# apollo4b register map
Vendor: Ambiq Micro; Series: Apollo; File version: 1.0
CPU: CM4 r1p0, little endian, MPU, FPU, I-cache, D-cache, VTOR, ITCM, DTCM, 3 interrupt priority bits, 0 interrupts
Registers are 32-bit, read-write, reset 0x0 unless marked. A register's access mark holds for its fields unless they carry their own. Offsets are from the block's base; [hi:lo] are bit positions; 'fields as' and 'values as' point back to an identical list.

## IOM0 — IO Peripheral Master
Base 0x40050000
Same registers: IOM1 0x40051000, IOM2 0x40052000, IOM3 0x40053000, IOM4 0x40054000, IOM5 0x40055000, IOM6 0x40056000, IOM7 0x40057000
0x00 FIFO — Provides direct random access to both input and output fifos. The state of the FIFO is not distured by reading these locations (ie no POP will be done). FIFO0 is accessible from addresses 0x0 - 0x1C, and is used for data outuput from the IOM to external devices. These FIFO locations can be read and written directly. FIFO locations 0x20 - 0x3C provide read only access to the input fifo. These FIFO locations cannot be directly written by the MCU, and are updated only by the internal hardware. Writes to the FIFO0 will take effect immediately. The currently FIFO pointers in register FIFOLOC indicate the current offset into each FIFO0 for the read and write operations. Access to the FIFOs can only be done in word increments; Byte access and writes are not supported. For push and pop style access to FIFO0 can be done using the FIFOPOP and FIFOPUSH registers below.
  [31:0] FIFO — FIFO direct access. Only locations 0 - 3F will return valid information.
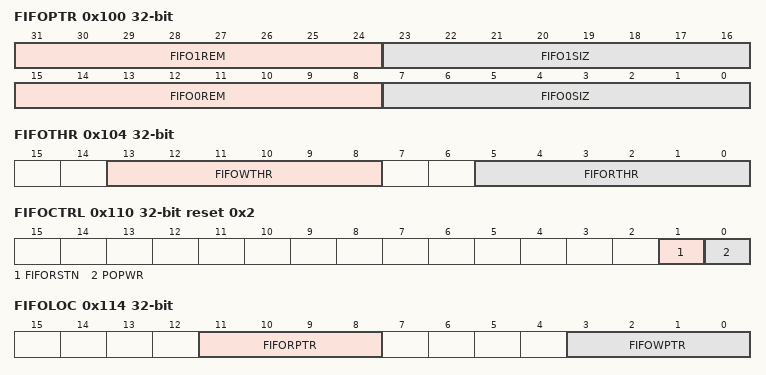
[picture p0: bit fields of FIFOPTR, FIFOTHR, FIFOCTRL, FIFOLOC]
0x100 FIFOPTR — Provides the current valid byte count of data within the FIFO as seen from the internal state machines. FIFO0 is dedicated to outgoing transactions and FIFO1 is dedicated to incoming transactions. All counts are specified in units of bytes.
  [31:24] FIFO1REM — The number of remaining data bytes slots currently in FIFO 1 (written by interface, read by MCU)
  [23:16] FIFO1SIZ — The number of valid data bytes currently in FIFO 1 (written by interface, read by MCU)
  [15:8] FIFO0REM — The number of remaining data bytes slots currently in FIFO 0 (written by MCU, read by interface)
  [7:0] FIFO0SIZ — The number of valid data bytes currently in the FIFO 0 (written by MCU, read by interface)
0x104 FIFOTHR — Sets the threshold values for incoming and outgoing transactions. The threshold values are used to assert the interrupt if enabled, and also used during DMA to set the transfer size as a result of DMATHR trigger. The WTHR is used to indicate when there are more than WTHR bytes of open fifo locations available in the outgoing FIFO (FIFO0). The intended use to invoke an interrupt or DMA transfer that will refill the FIFO with a byte count up to this value. The RTHR is used to indicate when there are more than RTHR bytes in the incoming FIFO (FIFO1) and a data transfer of this size can be supported, either through direct POP of the FIFO, or through DMA. The value of both RTHR and WTHR are also used to set the data transfer size of DMA operations if DMATHR trigger is enabled.
  [13:8] FIFOWTHR — FIFO write threshold in bytes. A value of 0 will disable the write FIFO level from activating the threshold interrupt. If this field is non-zero, it will trigger a threshold interrupt when the write fifo contains FIFOWTHR free bytes, as indicated by the FIFO0REM field. This is intended to signal when a transfer of FIFOWTHR bytes can be done from the host to the IOM write fifo to support large IOM write operations.
  [5:0] FIFORTHR — FIFO read threshold in bytes. A value of 0 will disable the read FIFO level from activating the threshold interrupt. If this field is non-zero, it will trigger a threshold interrupt when the read fifo contains FIFORTHR valid bytes of data, as indicated by the FIFO1SIZ field. This is intended to signal when a data transfer of FIFORTHR bytes can be done from the IOM module to the host via the read fifo to support large IOM read operations.
0x108 FIFOPOP — Will advance the internal read pointer of the incoming FIFO (FIFO1) when read, if POPWR is not active. If POPWR is active, a write to this register is needed to advance the internal FIFO pointer.
  [31:0] FIFODOUT — This register will return the read data indicated by the current read pointer on reads. If the POPWR control bit in the FIFOCTRL register is reset (0), the fifo read pointer will be advanced by one word as a result of the read. If the POPWR bit is set (1), the fifo read pointer will only be advanced after a write operation to this register. The write data is ignored for this register. If less than a even word multiple is available, and the command is completed, the module will return the word containing these bytes and undetermined data in the unused fields of the word.
0x10C FIFOPUSH — Will write new data into the outgoing FIFO and advance the internal write pointer.
  [31:0] FIFODIN — This register is used to write the FIFORAM in FIFO mode and will cause a push event to occur to the next open slot within the FIFORAM. Writing to this register will cause the write point to increment by 1 word(4 bytes).
0x110 FIFOCTRL reset 0x2 — Provides controls for the operation of the internal FIFOs. Contains fields used to control the operation of the POP register, and also controls to reset the internal pointers of the FIFOs.
  [1] FIFORSTN — Active low manual reset of the fifo. Write to 0 to reset fifo, and then write to 1 to remove the reset.
  [0] POPWR — Selects the mode in which 'pop' events are done for the fifo read operations. A value of '1' will prevent a pop event on a read operation, and will require a write to the FIFOPOP register to create a pop event. A value of '0' in this register will allow a pop event to occur on the read of the FIFOPOP register, and may cause inadvertant fifo pops when used in a debugging mode.
0x114 FIFOLOC — Provides a read only value of the current read and write pointers. This register is read only and can be used alogn with the FIFO direct access method to determine the next data to be used for input and output functions.
  [11:8] FIFORPTR — Current FIFO read pointer. Used to index into the incoming FIFO (FIFO1), which is used to store read data returned from external devices during a read operation.
  [3:0] FIFOWPTR — Current FIFO write pointer. Value is the index into the outgoing FIFO (FIFO0), which is used during write operations to external devices.
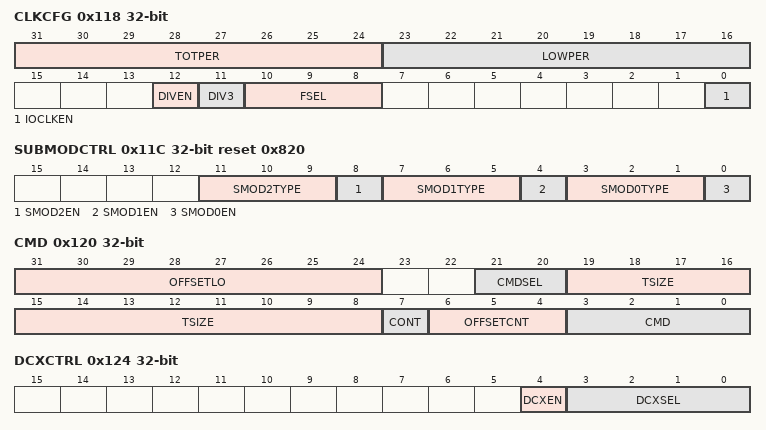
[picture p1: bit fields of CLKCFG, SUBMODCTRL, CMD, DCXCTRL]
0x118 CLKCFG — Provides clock related controls used internal to the BLEIF module, and enablement of 32KHz clock to the BLE Core module. The internal clock sourced is selected via the FSEL and can be further divided by 3 using the DIV3 control. This register is also used to enable the clock, which must be done prior to performing any IO transactions.
  [31:24] TOTPER — Clock total clock count minus 1. This provides the total period of the divided clock -1 when the DIVEN is active. The source clock is selected by FSEL. Only applicable when DIVEN = 1.
  [23:16] LOWPER — Clock low clock count minus 1. This provides the number of clocks the divided clock will be low when the DIVEN = 1. Only applicable when DIVEN = 1.
  [12] DIVEN — Enable clock division by TOTPER and LOWPER
    0=DIS (Disable TOTPER division.); 1=EN (Enable TOTPER division.)
  [11] DIV3 — Enable divide by 3 of the source IOCLK. Division by 3 is done before the DIVEN programmable divider, and if enabled will provide the divided by 3 clock as the source to the programmable divider.
    0=DIS (Select divide by 1.); 1=EN (Select divide by 3.)
  [10:8] FSEL — Select the input clock frequency.
    0=MIN_PWR (Selects the minimum power clock. This setting should be used whenever the IOM is not active.); 1=OFF (Selects static 0 as the input clock. Previously 96Mhz setting); 2=HFRC48MHZ (Selects the HFRC 48MHz as the input clock.); 3=HFRC24MHZ (Selects the HFRC 24MHz as the input clock.); 4=HFRC12MHZ (Selects the HFRC 12MHz as the input clock.); 5=HFRC6MHZ (Selects the HFRC 6MHz as the input clock.); 6=HFRC3MHZ (Selects the HFRC 3MHz as the input clock.); 7=HFRC1p5MHZ (Selects the HFRC 1.5MHz as the input clock.)
  [0] IOCLKEN — Enable for the interface clock. Must be enabled prior to executing any IO operations.
0x11C SUBMODCTRL reset 0x820 — Provides enable for each submodule. Only a sigle submodule can be enabled at one time.
  [11:9] SMOD2TYPE — Submodule 2 module type. This is the I2S Master/Slave interface
    0=MSPI (SPI Master submodule); 1=MI2C (MI2C submodule); 2=SSPI (SPI Slave submodule); 3=SI2C (I2C Slave submodule); 4=MSI2S (Master/Slave submodule); 7=NA (NOT INSTALLED)
  [8] SMOD2EN — Submodule 2 enable (1) or disable (0)
  [7:5] SMOD1TYPE — Submodule 1 module type. This is the I2C Master interface
    values as SMOD2TYPE
  [4] SMOD1EN — Submodule 1 enable (1) or disable (0)
  [3:1] SMOD0TYPE — Submodule 0 module type. This is the SPI Master interface.
    0=MSPI (MSPI submodule); 1=MI2C (I2C Master submodule); 2=MSI2S (I2S Master/Slave Module); 7=NA (NOT INSTALLED)
  [0] SMOD0EN — Submodule 0 enable (1) or disable (0)
0x120 CMD — Writes to this register will start an IO transaction, as well as set various parameters for the command itself. Reads will return the command value written to the CMD register. To read the number of bytes that have yet to be transferred, refer to the CTSIZE field within the CMDSTAT register.
  [31:24] OFFSETLO — This register holds the low order byte of offset to be used in the transaction. The number of offset bytes to use is set with bits 1:0 of the command.
  [21:20] CMDSEL — Command Specific selection information. Not used in Master I2C. Used as CEn select for Master SPI transactions
  [19:8] TSIZE — Defines the transaction size in bytes. The offset transfer is not included in this size.
  [7] CONT — Contine to hold the bus after the current transaction if set to a 1 with a new command issued.
  [6:4] OFFSETCNT — Number of offset bytes to use for the command - 0, 1, 2, 3, 4, 5 are valid selections. The second (byte 1),third (byte 2), and forth (byte 3) are read from the OFFSETHI register, and the low order byte is pulled from this register in the OFFSETLO field. Offset bytes are transmitted highest byte first. EG if offsetcnt == 4, OFFSETHI[23:16] will be transmitted first, then OFFSETHI[15:8], then OFFSETHI[7:0] then OFFSETLO. If offsetcnt == 5, OFFSETHI[31:24] will be transmitted, then OFFSETHI[23:0], then OFFSETLO. If offsetcnt == 4, OFFSETHI[23:16] will be transmitted, then OFFSETHI[15:0], then OFFSETLO. If offsetcnt == 3, OFFSETHI[15:8] will be transmitted, then OFFSETHI[7:0], then OFFSETLO. If offsetcnt == 2, OFFSETHI[7:0] will be transmitted, then OFFSETLO. If offsetcnt == 1, only OFFSETLO will be transmitted. Offset bytes are always transmitted MSB first, regardless of the value of the LSB control bit within the module configuration.
  [3:0] CMD — Command for submodule.
    1=WRITE (Write command using count of offset bytes specified in the OFFSETCNT field); 2=READ (Read command using count of offset bytes specified in the OFFSETCNT field); 3=TMW (SPI only. Test mode to do constant write operations. Useful for debug and power measurements. Will continually send data in OFFSET field); 4=TMR (SPI Only. Test mode to do constant read operations. Useful for debug and power measurements. Will continually read data from external input)
0x124 DCXCTRL — Enables transmission of DCX signal with SPI transactions and selects which CE signals will be used to transmit the DCX signal.
  [4] DCXEN — Global enable of the DCX function. Setting to 1 will enable the generation of the DCX signal, which will assert when sending the offset bytes of the SPI transaction.
  [3:0] DCXSEL — Selects the CE channel used to convey the DCX function. The select is bitwise encoded, with bit 0 = 1 enabling CE0 for DCX transmission, bit 1 = 1 enableing CE1 for DCX transmission, etc. If the CE used for the SPI transaction is set, it will be ignored and used as the transaction CE instead. Multiple CE channels can be selected at once. To enable the DCX signal to be transmitted out of the chip, the corresponding pin mux function must be enabled in the GPIO logic as well.
0x128 OFFSETHI — High order bytes of offset for IO transaction
  [31:0] OFFSETHI — Holds the high order bytes of the byte addressing/offset field to use with IO commands. The number of offset bytes to use is specified in the command register
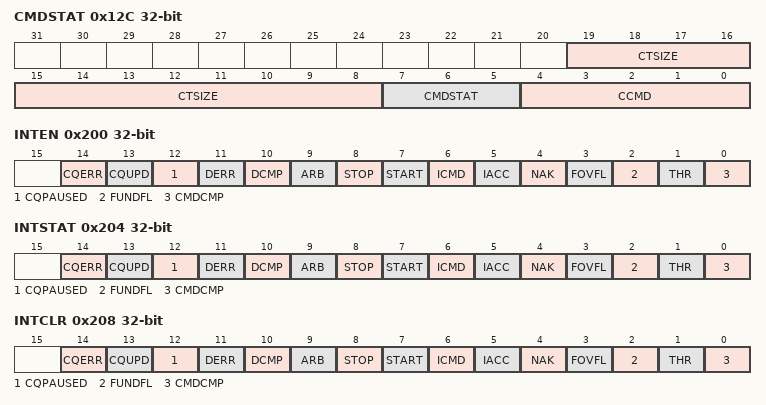
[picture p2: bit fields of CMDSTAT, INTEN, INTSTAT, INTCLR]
0x12C CMDSTAT — Provides staus on the execution of the command currently in progress. The fields in this register will reflect the real time status of the internal state machines and data transfers within the IOM. These are read only fields and writes to the registers are ignored.
  [19:8] CTSIZE — The current number of bytes still to be transferred with this command. This field will count down to zero.
  [7:5] CMDSTAT — The current status of the command execution.
    1=ERR (Error encountered with command); 2=ACTIVE (Actively processing command); 4=IDLE (Idle state, no active command, no error); 6=WAIT (Command in progress, but waiting on data from host)
  [4:0] CCMD — Current command that is being executed; This will update based on the phase of the I2C, and will indicate a write operation during transmission of the offset, and then the programmed command. After the command is completed, it will be cleared to zero. (Note this field is defined as 5b, but top bit is unsed, and matches the size of the CMD field in the IOM_CMD register )
0x200 INTEN — Set bits in this register to allow this module to generate the corresponding interrupt.
  [14] CQERR — Error during command queue operations
  [13] CQUPD — CQ write operation performed a register write with the register address bit 0 set to 1. The low address bits in the CQ address fields are unused and bit 0 can be used to trigger an interrupt to indicate when this register write is performed by the CQ operation.
  [12] CQPAUSED — Command queue is paused due to an active event enabled in the PAUSEEN register. The interrupt is posted when the event is enabled within the PAUSEEN register, the mask is active in the CQIRQMASK field and the event occurs.
  [11] DERR — DMA Error encountered during the processing of the DMA command. The DMA error could occur when the memory access specified in the DMA operation is not available or incorrectly specified.
  [10] DCMP — DMA Complete. Processing of the DMA operation has completed and the DMA submodule is returned into the idle state
  [9] ARB — Arbitration loss interrupt. Asserted when arbitration is enabled and has been lost to another master on the bus. Also asserted during I2C write operations when value of 1 expected on bus, but 0 is observed. When asserted, the I2C state machine will immediately go to idle. This interrupt condition is cleared by the next command.
  [8] STOP — STOP command interrupt. Asserted when another master on the bus has signaled a STOP command.
  [7] START — START command interrupt. Asserted when another master on the bus has signaled a START command.
  [6] ICMD — illegal command interrupt. Asserted when a command is written when an active command is in progress.
  [5] IACC — illegal FIFO access interrupt. Asserted when there is a overflow or underflow event
  [4] NAK — I2C NAK interrupt. Asserted when an unexpected NAK has been received on the I2C bus.
  [3] FOVFL — Write FIFO Overflow interrupt. This occurs when software tries to write to a full fifo. The current operation does not stop.
  [2] FUNDFL — Read FIFO Underflow interrupt. This occurs when software tries to pop from an empty fifo.
  [1] THR — FIFO Threshold interrupt. For write operations, asserted when the number of free bytes in the write FIFO equals or exceeds the WTHR field. For read operations, asserted when the number of valid bytes in the read FIFO equals of exceeds the value set in the RTHR field.
  [0] CMDCMP — Command Complete interrupt. Asserted when the current operation has completed. For repeated commands, this will only be asserted when the final repeated command is completed.
0x204 INTSTAT — Read bits from this register to discover the cause of a recent interrupt.
  fields as INTEN
0x208 INTCLR — Write a 1 to a bit in this register to clear the interrupt status associated with that bit.
  fields as INTEN
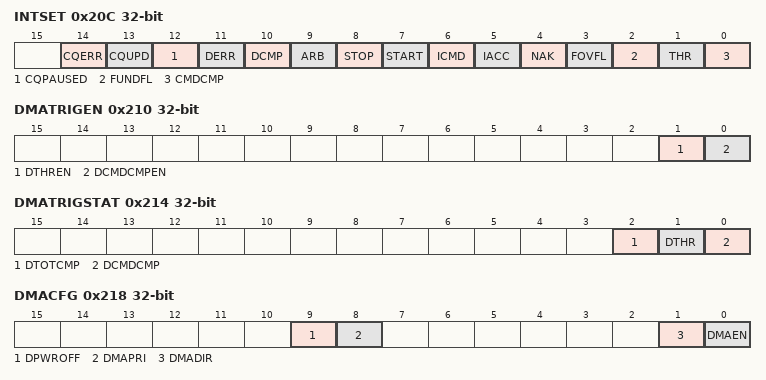
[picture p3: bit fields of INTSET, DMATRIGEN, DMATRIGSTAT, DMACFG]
0x20C INTSET — Write a 1 to a bit in this register to instantly generate an interrupt from this module. (Generally used for testing purposes).
  fields as INTEN
0x210 DMATRIGEN — Provides control on which event will trigger the DMA transfer after the DMA operation is setup and enabled. The trigger event will cause a number of bytes (depending on trigger event) to be transferred via the DMA operation, and can be used to adjust the latency of data to/from the IOM module to/from the dma target. DMA transfers are broken into smaller transfers internally of up to 16 bytes each, and multiple trigger events can be used to complete the entire programmed DMA transfer.
  [1] DTHREN — Trigger DMA upon THR level reached. For M2P DMA operations (IOM writes), the trigger will assert when the write FIFO has (WTHR/4) number of words free in the write FIFO, and will transfer (WTHR/4) number of words or, if the number of words left to transfer is less than the WTHR value, will transfer the remaining byte count. For P2M DMA operations, the trigger will assert when the read FIFO has (RTHR/4) words available in the read FIFO, and will transfer (RTHR/4) words to SRAM. This trigger will NOT assert when the transaction completes and there are less than RTHR bytes left in the fifo, since the RTHR has not been reached. In this case, the CMDCMP trigger must also be enabled to transfer the remaining read FIFO data to SRAM.
  [0] DCMDCMPEN — Trigger DMA upon command complete. Enables the trigger of the DMA when a command is completed. When this event is triggered, the number of words transferred will be the lesser of the remaining TOTCOUNT bytes, or
0x214 DMATRIGSTAT — Provides the status of trigger events that have occurred for the transaction. Some of the bits are read only and some can be reset via a write of 0.
  [2] DTOTCMP — DMA triggered when DCMDCMP = 0, and the amount of data in the FIFO was enough to complete the DMA operation (greater than or equal to current TOTCOUNT) when the command completed. This trigger is default active when the DCMDCMP trigger is disabled and there is enough data in the FIFO to complete the DMA operation.
  [1] DTHR — Triggered DMA from THR event. Bit is read only and can be cleared by disabling the DTHR trigger enable or by disabling DMA.
  [0] DCMDCMP — Triggered DMA from Command complete event. Bit is read only and can be cleared by disabling the DCMDCMP trigger enable or by disabling DMA.
0x218 DMACFG — Configuration control of the DMA process, including the direction of DMA, and enablement of DMA
  [9] DPWROFF — Power off module after DMA is complete. If this bit is active, the module will request to power off the supply it is attached to. If there are other units still requiring power from the same domain, power down will not be performed.
    0=DIS (Power off disabled); 1=EN (Power off enabled)
  [8] DMAPRI — Sets the Priority of the DMA request
    0=LOW (Low Priority (service as best effort)); 1=HIGH (High Priority (service immediately))
  [1] DMADIR — Direction
    0=P2M (Peripheral to Memory (SRAM) transaction. To be set when doing IOM read operations, ie reading data from external devices.); 1=M2P (Memory to Peripheral transaction. To be set when doing IOM write operations, ie writing data to external devices.)
  [0] DMAEN — DMA Enable. Setting this bit to EN will start the DMA operation. This should be the last DMA related register set prior to issuing the command
    0=DIS (Disable DMA Function); 1=EN (Enable DMA Function)
0x21C DMATOTCOUNT — Contains the number of bytes to be transferred for this DMA transaction. This register is decremented as the data is transferred, and will be 0 at the completion of the DMA operation.
  [11:0] TOTCOUNT — Triggered DMA from Command complete event occured. Bit is read only and can be cleared by disabling the DTHR trigger enable or by disabling DMA.
0x220 DMATARGADDR — The source or destination address internal the SRAM for the DMA data. For write operations, this can only be SRAM data (ADDR bit 28 = 1); For read operations, this can ve either SRAM or FLASH (ADDR bit 28 = 0)
  [28:0] TARGADDR — Bits [28:0] of the target byte address for source of DMA (either read or write). The address can be any byte alignment, and does not have to be word aligned. In cases of non-word aligned addresses, the DMA logic will take care for ensuring only the target bytes are read/written.
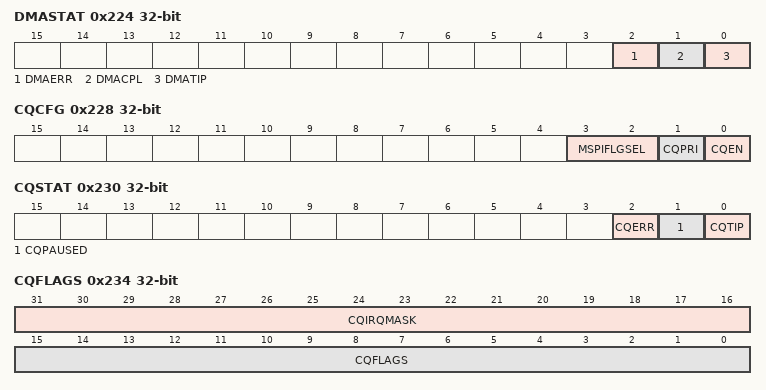
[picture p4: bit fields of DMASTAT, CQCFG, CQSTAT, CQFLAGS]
0x224 DMASTAT — Status of the DMA operation currently in progress.
  [2] DMAERR — DMA Error. This active high bit signals an error was encountered during the DMA operation. The bit can be cleared by writing to 0. Once set, this bit will remain set until cleared by software.
  [1] DMACPL — DMA Transfer Complete. This signals the end of the DMA operation. This bit can be cleared by writing to 0, and will also be cleared when a new DMA is started.
  [0] DMATIP — DMA Transfer In Progress indicator. 1 will indicate that a DMA transfer is active. The DMA transfer may be waiting on data, transferring data, or waiting for priority. All of these will be indicated with a 1. A 0 will indicate that the DMA is fully complete and no further transactions will be done. This bit is read only.
0x228 CQCFG — Controls parameters and options for execution of the command queue operation. To enable command queue, create this in memory, set the address, and enable it with a write to CQEN
  [3:2] MSPIFLGSEL — Selects the MPSI modules used for sourcing the CQFLAG [11:8].
    0=MSPI0FLGSEL (Selects MPSI0 as source of signals used in CGFLAG[11:8].); 1=MSPI1FLGSEL (Selects MPSI1 as source of signals used in CGFLAG[11:8].); 2=MSPI2FLGSEL (Selects MPSI2 as source of signals used in CGFLAG[11:8].)
  [1] CQPRI — Sets the Priority of the command queue dma request
    values as DMACFG.DMAPRI
  [0] CQEN — Command queue enable. When set, will enable the processing of the command queue and fetches of address/data pairs will proceed from the word address within the CQADDR register. Can be disabled using a CQ executed write to this bit as well.
    0=DIS (Disable CQ Function); 1=EN (Enable CQ Function)
0x22C CQADDR — The SRAM address which will be fetched next execution of the CQ operation. This register is updated as the CQ operation progresses, and is the live version of the register. The register can also be written by the Command Queue operation itself, allowing the relocation of successive CQ fetches. In this case, the new CQ address will be used for the next CQ address/data fetch
  [28:2] CQADDR — Bits 28:2 of target byte address for source of CQ . The buffer must be aligned on a word boundary
0x230 CQSTAT — Provides the status of the command queue operation. If the command queue is disabled, these bits will be cleared. The bits are read only
  [2] CQERR — Command queue processing Error. This active high bit signals that an error was encountered during the CQ operation.
  [1] CQPAUSED — Command queue operation is currently paused.
  [0] CQTIP — Command queue Transfer In Progress indicator. 1 will indicate that a CQ transfer is active and this will remain active even when paused waiting for external event.
0x234 CQFLAGS — Command Queue Flag
  [31:16] CQIRQMASK — Mask the bits used to generate the command queue interrupt. A '1' in the bit position will enable the pause event to trigger the interrupt, if the CQWT_int interrupt is enabled. Bits definitions are the same as CQPAUSE
  [15:0] CQFLAGS — Current flag status (read-only). Bits [7:0] are software controllable and bits [15:8] are hardware status.
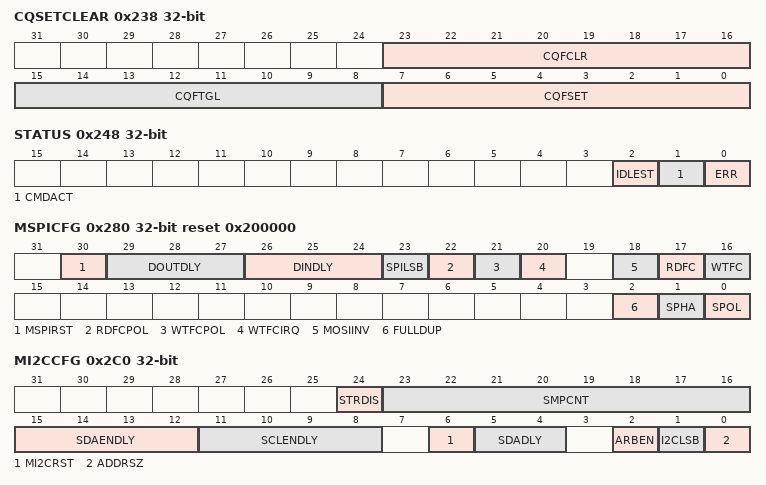
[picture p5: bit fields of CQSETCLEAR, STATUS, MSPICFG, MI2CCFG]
0x238 CQSETCLEAR — Set/Clear the command queue software pause flags on a per-bit basis. Contains 3 fields, allowing for setting, clearing or toggling the value in the software flags. Priority when the same bit is enabled in each field is toggle, then set, then clear.
  [23:16] CQFCLR — Clear CQFlag status bits. Will clear to 0 any SWFLAG with a '1' in the corresponding bit position of this field
  [15:8] CQFTGL — Toggle the indicated bit. Will toggle the value of any SWFLAG with a '1' in the corresponding bit position of this field
  [7:0] CQFSET — Set CQFlag status bits. Will set to 1 the value of any SWFLAG with a '1' in the corresponding bit position of this field
0x23C CQPAUSEEN — Enables a flag to pause an active command queue operation. If a bit is '1' and the corresponding bit in the CQFLAG register is '1', CQ processing will halt until either value is changed to '0'.
  [15:0] CQPEN — Enables the specified event to pause command processing when active
    0x8000=IDXEQ (Pauses the command queue when the current index matches the last index); 0x4000=BLEXOREN (Pause command queue when input BLE bit XORed with SWFLAG4 is '1'); 0x2000=IOMXOREN (Pause command queue when input IOM bit XORed with SWFLAG3 is '1'); 0x1000=GPIOXOREN (Pause command queue when input GPIO irq_bit XORed with SWFLAG2 is '1'); 0x800=MSPI1XNOREN (Pause command queue when input MSPI1 bit XNORed with SWFLAG1 is '1'); 0x400=MSPI0XNOREN (Pause command queue when input MSPI0 bit XNORed with SWFLAG0 is '1'); 0x200=MSPI1XOREN (Pause command queue when input MSPI1 bit XORed with SWFLAG1 is '1'); 0x100=MSPI0XOREN (Pause command queue when input MSPI0 bit XORed with SWFLAG0 is '1'); 128=SWFLAGEN7 (Pause the command queue when software flag bit 7 is '1'.); 64=SWFLAGEN6 (Pause the command queue when software flag bit 6 is '1'); 32=SWFLAGEN5 (Pause the command queue when software flag bit 5 is '1'); 16=SWFLAGEN4 (Pause the command queue when software flag bit 4 is '1'); 8=SWFLAGEN3 (Pause the command queue when software flag bit 3 is '1'); 4=SWFLAGEN2 (Pause the command queue when software flag bit 2 is '1'); 2=SWFLAGEN1 (Pause the command queue when software flag bit 1 is '1'); 1=SWFLAGEN0 (Pause the command queue when software flag bit 0 is '1')
0x240 CQCURIDX — Current index value, targeted to be written by register write operations within the command queue. This is compared to the CQENDIDX and will stop the CQ operation if bit 15 of the CQPAUSEEN is '1' and this current index equals the CQENDIDX register value. This will only pause when the values are equal.
  [7:0] CQCURIDX — Holds 8 bits of data that will be compared with the CQENDIX register field. If the values match, the IDXEQ pause event will be activated, which will cause the pausing of command quue operation if the IDXEQ bit is enabled in CQPAUSEEN.
0x244 CQENDIDX — End index value, targeted to be written by software to indicate the last valid register pair contained within the command queue. rgister write operations within the command queue. This is compared to the CQCURIDX and will stop the CQ operation if bit 15 of the CQPAUSEEN is '1' and this current index equals the CQCURIDX register value. This will only pause when the values are equal.
  [7:0] CQENDIDX — Holds 8 bits of data that will be compared with the CQCURIX register field. If the values match, the IDXEQ pause event will be activated, which will cause the pausing of command quue operation if the IDXEQ bit is enabled in CQPAUSEEN.
0x248 STATUS — IOM Module Status
  [2] IDLEST — indicates if the active I/O state machine is IDLE. Note - The state machine could be in idle state due to holdoffs from data availability, or as the command gets propagated into the logic from the registers.
    1=IDLE (The I/O state machine is in the idle state.)
  [1] CMDACT — Indicates if the active I/O Command is currently processing a transaction, or command is complete, but the FIFO pointers are still syncronizing internally. This bit will go high at the start of the transaction, and will go low when the command is complete, and the data and pointers within the FIFO have been syncronized.
    1=ACTIVE (An I/O command is active. Indicates the active module has an active command and is processing this. De-asserted when the command is completed.)
  [0] ERR — Bit has been deprecated. Please refer to the other error indicators. This will always return 0.
    1=ERROR (Bit has been deprecated and will always return 0.)
0x280 MSPICFG reset 0x200000 — Controls the configuration of the SPI master module, including POL/PHA, LSB, flow control, and delays for MISO and MOSI
  [30] MSPIRST — Not used. To reset the module, toggle the SMOD_EN for the module
  [29:27] DOUTDLY — Delay tap to use for the output signal (MOSI). This give more hold time on the output data
  [26:24] DINDLY — Delay tap to use for the input signal (MISO). This gives more hold time on the input data.
  [23] SPILSB — Selects data transfer as MSB first (0) or LSB first (1) for the data portion of the SPI transaction. The offset bytes are always transmitted MSB first.
    0=MSB (Send and receive MSB bit first); 1=LSB (Send and receive LSB bit first)
  [22] RDFCPOL — Selects the read flow control signal polarity.
    0=HIGH (Flow control signal high creates flow control.); 1=LOW (Flow control signal low creates flow control.)
  [21] WTFCPOL — selects the write flow control signal polarity. The transfers are halted when the selected flow control signal is OPPOSITE polarity of bit. (For example: WTFCPOL = 0 will allow a IRQ=1 to pause transfers).
    0=HIGH (Flow control signal high(1) creates flow control and byte transfers will stop until the flow control signal goes low.); 1=LOW (Flow control signal low(0) creates flow control and byte transfers will stop until the flow control signal goes high(1).)
  [20] WTFCIRQ — Selects the write mode flow control signal.
    0=MISO (MISO is used as the write mode flow control signal.); 1=IRQ (IRQ is used as the write mode flow control signal.)
  [18] MOSIINV — Inverts MOSI when flow control is enabled.
    0=NORMAL (MOSI is set to 0 in read mode and 1 in write mode.); 1=INVERT (MOSI is set to 1 in read mode and 0 in write mode.)
  [17] RDFC — Enables read mode flow control.
    0=DIS (Read mode flow control disabled.); 1=EN (Read mode flow control enabled.)
  [16] WTFC — enables write mode flow control.
    0=DIS (Write mode flow control disabled.); 1=EN (Write mode flow control enabled.)
  [2] FULLDUP — Enables full duplex mode for Master SPI write operations. Data will be captured simultaneously into the read fifo
  [1] SPHA — Selects SPI phase.IMPORTANT NOTICE: Due to the susceptibility of creating a clock glitch which could cause register corruption, changing SPHA and SPOL bits should be done in separate writes to this register.
    0=SAMPLE_LEADING_EDGE (Sample on the leading (first) clock edge.); 1=SAMPLE_TRAILING_EDGE (Sample on the trailing (second) clock edge.)
  [0] SPOL — Selects SPI polarity.IMPORTANT NOTICE: Due to the susceptibility of creating a clock glitch which could cause register corruption, changing SPHA and SPOL bits should be done in separate writes to this register.
    0=CLK_BASE_0 (The base value of the clock is 0.); 1=CLK_BASE_1 (The base value of the clock is 1.)
0x2C0 MI2CCFG — Controls the configuration of the I2C bus master.
  [24] STRDIS — Disable detection of clock stretch events smaller than 1 cycle
  [23:16] SMPCNT — Number of Base clk cycles to wait before sampling the SCL clock to determine if a clock stretch event has occured
  [15:12] SDAENDLY — Number of IOCLK cycles to delay the SDA output en (all transitions affected). Used to delay data relative to clock
  [11:8] SCLENDLY — Number of IOCLK cycles to delay the rising edge of the SCL output en (clock will go low on this edge). Used to allow clock shaping.
  [6] MI2CRST — Not used. To reset the module, toggle the SMOD_EN for the module
  [5:4] SDADLY — Delay to enable on the SDA output. Values are 0x0-0x3.
  [2] ARBEN — Enables multi-master arbitration for the I2C master. If the bus is known to have only a single master, this function can be disabled to save clock cycles on I2C transactions
    1=ARBENABLE (Enable multi-master bus arbitration support for this i2c master); 0=ARBDISABLE (Disable multi-master bus arbitration support for this i2c master)
  [1] I2CLSB — Direction of data transmit and receive, MSB(0) or LSB(1) first. Default per I2C specification is MSB first. This applies to both read and write data, and read data will be bit
    0=MSBFIRST (Byte data is transmitted MSB first onto the bus/read from the bus); 1=LSBFIRST (Byte data is transmitted LSB first onto the bus/read from the bus)
  [0] ADDRSZ — Sets the I2C master device address size to either 7b (0) or 10b (1).
    0=Use 7b addressing for I2C master transactions; 1=Use 10b addressing for I2C master transactions
0x2C4 DEVCFG — Contains the I2C device address.
  [9:0] DEVADDR — I2C address of the device that the Master will use to target for read/write operations. This can be either a 7b or 10b address.
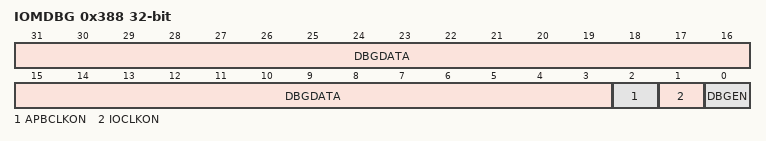
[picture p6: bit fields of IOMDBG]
0x388 IOMDBG — Debug control
  [31:3] DBGDATA — Debug control for various options. DBGDATA[1:0] is used to select between different debug data available in the DBG0 and DBG1 registers.
  [2] APBCLKON — APBCLK debug clock control. Enable APB_CLK to be active when this bit is '1'. Otherwise, the clock is controlled with gating from the logic as needed.
  [1] IOCLKON — IOCLK debug clock control. Enable IO_CLK to be active when this bit is '1'. Otherwise, the clock is controlled with gating from the logic as needed.
  [0] DBGEN — Debug Enable. Setting bit will enable the update of data within this register, otherwise it is clock gated for power savings
